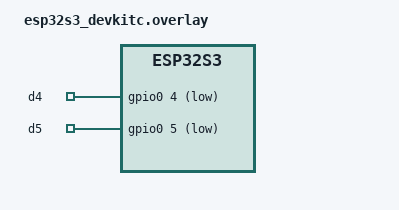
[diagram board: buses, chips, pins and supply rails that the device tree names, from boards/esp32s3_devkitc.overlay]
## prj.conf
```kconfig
CONFIG_GPIO=y
CONFIG_CUSTOM_BUTTON=y
CONFIG_LOG=y
CONFIG_LOG_DEFAULT_LEVEL=4
```

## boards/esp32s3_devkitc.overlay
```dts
/ {
    aliases {
        my-button-1 = &button_1;
        my-button-2 = &button_2;
    };

    custom-buttons {
        button_1: custom_button_1 {
            compatible = "custom,button";
            pin = <&d4>;
        };
        
        button_2: custom_button_2 {
            compatible = "custom,button";
            pin = <&d5>;
        };
    };

    gpio-keys {
        compatible = "gpio-keys";
        debounce-interval-ms = <50>;
        polling-mode;

        d4: gpio4 {
            gpios = <&gpio0 4 (GPIO_ACTIVE_LOW | GPIO_PULL_UP)>;
        };

        d5: gpio5 {
            gpios = <&gpio0 5 (GPIO_ACTIVE_LOW | GPIO_PULL_UP)>;
        };
    };
};
```

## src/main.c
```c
#include <stdio.h>
#include <zephyr/kernel.h>

#include "button.h"

// Settings
static const int32_t sleep_time_ms = 100;
static const struct device *btn = DEVICE_DT_GET(DT_ALIAS(my_button));

int main(void)
{
    int ret;
    uint8_t state;

    // Make sure that the button was initialized
    if (!device_is_ready(btn)) {
        printk("ERROR: button not ready\r\n");
        return 0;
    }

    // Get the API for the button
    const struct button_api *btn_api = (const struct button_api *)btn->api;

    // Do forever
    while (1) {
        
        // Poll button state
        ret = btn_api->get(btn, &state);
        if (ret < 0) {
            printk("Error %d: failed to read button pin\r\n", ret);
            continue;
        }
        printk("Button state: %d\r\n", state);

        // Sleep
        k_msleep(sleep_time_ms);
    }

    return 0;
}
```
